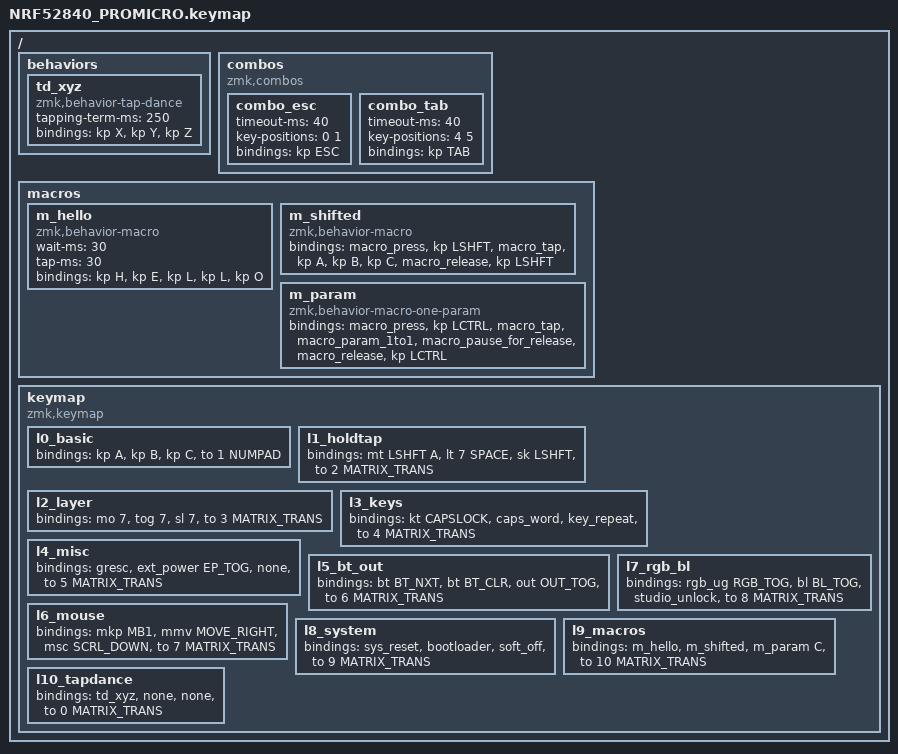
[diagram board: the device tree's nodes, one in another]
#include <behaviors.dtsi>
#include <dt-bindings/zmk/keys.h>
#include <dt-bindings/zmk/bt.h>
#include <dt-bindings/zmk/outputs.h>
#include <dt-bindings/zmk/pointing.h>
#include <dt-bindings/zmk/rgb.h>
#include <dt-bindings/zmk/backlight.h>
#include <dt-bindings/zmk/ext_power.h>

// Position layout (16 keys/layer) — same shape as the DK build, but every
// key is on a broken-out Pro Micro pad (see the .overlay for pin mapping):
//
//   pos 0  = direct key 0 (P0.06)
//   pos 1  = direct key 1 (P0.08)
//   pos 2  = direct key 2 (P0.17)
//   pos 3  = direct key 3 (P0.20) — always &to next-layer
//
//   pos 4  pos 5  pos 6      ← matrix row 0
//   pos 7  pos 8  pos 9      ← matrix row 1
//   pos 10 pos 11 pos 12     ← matrix row 2
//   pos 13 pos 14 pos 15     ← matrix row 3
//
// On L0 the matrix is a numpad. On every other layer the matrix is &trans,
// so it always types numbers regardless of which behavior layer the direct
// keys selected. Edit any matrix slot to change.

#define NUMPAD &kp N1 &kp N2 &kp N3   \
               &kp N4 &kp N5 &kp N6   \
               &kp N7 &kp N8 &kp N9   \
               &kp N0 &kp DOT &kp ENTER

#define MATRIX_TRANS &trans &trans &trans   \
                     &trans &trans &trans   \
                     &trans &trans &trans   \
                     &trans &trans &trans

/ {
    // User-defined behaviors (extends behaviors.dtsi). Studio renders
    // tap-dance entries under its Dynamic ▸ Tap Dance tab.
    behaviors {
        // Cycles X → Y → Z by tap count. tapping-term-ms is the
        // window in which a follow-up tap is treated as part of the
        // same dance instead of triggering the previous index.
        td_xyz: td_xyz {
            compatible = "zmk,behavior-tap-dance";
            #binding-cells = <0>;
            tapping-term-ms = <250>;
            bindings = <&kp X>, <&kp Y>, <&kp Z>;
        };
    };

    // Combos — fire a binding when listed key positions go down inside
    // timeout-ms of each other. Studio surfaces these under its Dynamic
    // ▸ Combos tab. Without a `layers` property a combo is global.
    combos {
        compatible = "zmk,combos";

        // Direct keys 0 + 1 chord → ESC. Tight 40 ms window so accidental
        // near-simultaneous presses don't trip it.
        combo_esc {
            timeout-ms = <40>;
            key-positions = <0 1>;
            bindings = <&kp ESC>;
        };

        // Matrix top-left two keys (positions 4 + 5) → TAB. Different
        // window/positions to exercise multiple combo entries.
        combo_tab {
            timeout-ms = <40>;
            key-positions = <4 5>;
            bindings = <&kp TAB>;
        };
    };

    // Macros under test. Three flavors cover the bulk of the ZMK macro
    // surface: zero-param tap sequence with timing overrides, manual
    // modifier press/release wrapping a tap burst, and a parametrized
    // (one-param) macro using &macro_param_1to1.
    macros {
        // Plain tap sequence — types "hello". Overrides default macro
        // timing so each tap holds 30 ms with a 30 ms gap; useful for
        // hosts that drop frames at ZMK's default 100 Hz cadence.
        m_hello: m_hello {
            compatible = "zmk,behavior-macro";
            #binding-cells = <0>;
            wait-ms = <30>;
            tap-ms = <30>;
            bindings = <&kp H &kp E &kp L &kp L &kp O>;
        };

        // Modifier-hold around a tap burst — types "ABC" by holding
        // LSHIFT across three letter taps, then releasing. Exercises
        // &macro_press / &macro_release instead of relying on &kp.
        m_shifted: m_shifted {
            compatible = "zmk,behavior-macro";
            #binding-cells = <0>;
            bindings
                = <&macro_press &kp LSHFT>
                , <&macro_tap &kp A &kp B &kp C>
                , <&macro_release &kp LSHFT>
                ;
        };

        // One-param macro — forwards its argument into the inner &kp via
        // &macro_param_1to1. Bound as `&m_param C` below for Ctrl+C, but
        // any keycode works as the param.
        m_param: m_param {
            compatible = "zmk,behavior-macro-one-param";
            #binding-cells = <1>;
            bindings
                = <&macro_press &kp LCTRL>
                , <&macro_tap &macro_param_1to1>
                , <&macro_pause_for_release>
                , <&macro_release &kp LCTRL>
                ;
        };
    };

    keymap {
        compatible = "zmk,keymap";

        // ─── L0 basic key-press ───
        l0_basic {
            bindings = <
                &kp A &kp B &kp C &to 1
                NUMPAD
            >;
        };

        // ─── L1 hold-tap + sticky-key ───
        l1_holdtap {
            bindings = <
                &mt LSHFT A &lt 7 SPACE &sk LSHFT &to 2
                MATRIX_TRANS
            >;
        };

        // ─── L2 layer behaviors (target = L7) ───
        l2_layer {
            bindings = <
                &mo 7 &tog 7 &sl 7 &to 3
                MATRIX_TRANS
            >;
        };

        // ─── L3 key-toggle / caps-word / key-repeat ───
        l3_keys {
            bindings = <
                &kt CAPSLOCK &caps_word &key_repeat &to 4
                MATRIX_TRANS
            >;
        };

        // ─── L4 misc — gresc / ext_power / none ───
        // (&trans is implicitly tested everywhere via layer fall-through.)
        l4_misc {
            bindings = <
                &gresc &ext_power EP_TOG &none &to 5
                MATRIX_TRANS
            >;
        };

        // ─── L5 bluetooth / output ───
        l5_bt_out {
            bindings = <
                &bt BT_NXT &bt BT_CLR &out OUT_TOG &to 6
                MATRIX_TRANS
            >;
        };

        // ─── L6 mouse — button / move / scroll ───
        l6_mouse {
            bindings = <
                &mkp MB1 &mmv MOVE_RIGHT &msc SCRL_DOWN &to 7
                MATRIX_TRANS
            >;
        };

        // ─── L7 RGB / backlight / studio ───
        l7_rgb_bl {
            bindings = <
                &rgb_ug RGB_TOG &bl BL_TOG &studio_unlock &to 8
                MATRIX_TRANS
            >;
        };

        // ─── L8 system reset / bootloader / soft-off ───
        l8_system {
            bindings = <
                &sys_reset &bootloader &soft_off &to 9
                MATRIX_TRANS
            >;
        };

        // ─── L9 macros — tap sequence / mod-wrapped burst / parametrized ───
        l9_macros {
            bindings = <
                &m_hello &m_shifted &m_param C &to 10
                MATRIX_TRANS
            >;
        };

        // ─── L10 tap-dance — single/double/triple tap cycles X/Y/Z ───
        l10_tapdance {
            bindings = <
                &td_xyz &none &none &to 0
                MATRIX_TRANS
            >;
        };
    };
};
